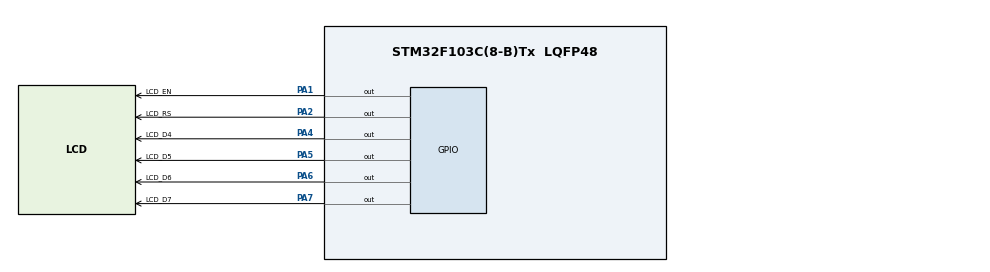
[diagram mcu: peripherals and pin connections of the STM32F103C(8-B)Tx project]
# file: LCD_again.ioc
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Mcu.Family=STM32F1
Mcu.Name=STM32F103C(8-B)Tx
Mcu.Package=LQFP48
NVIC.PriorityGroup=NVIC_PRIORITYGROUP_4
PA1.GPIO_Label=LCD_EN
PA1.Signal=GPIO_Output
PA13.Mode=Serial_Wire
PA13.Signal=SYS_JTMS-SWDIO
PA14.Mode=Serial_Wire
PA14.Signal=SYS_JTCK-SWCLK
PA2.GPIO_Label=LCD_RS
PA2.Signal=GPIO_Output
PA4.GPIO_Label=LCD_D4
PA4.Signal=GPIO_Output
PA5.GPIO_Label=LCD_D5
PA5.Signal=GPIO_Output
PA6.GPIO_Label=LCD_D6
PA6.Signal=GPIO_Output
PA7.GPIO_Label=LCD_D7
PA7.Signal=GPIO_Output
PD0-OSC_IN.Mode=HSE-External-Oscillator
PD0-OSC_IN.Signal=RCC_OSC_IN
PD1-OSC_OUT.Mode=HSE-External-Oscillator
PD1-OSC_OUT.Signal=RCC_OSC_OUT
ProjectManager.HeapSize=0x200
ProjectManager.StackSize=0x400
ProjectManager.TargetToolchain=MDK-ARM V5.32
RCC.APB1Freq_Value=8000000
RCC.APB2Freq_Value=8000000
board=custom

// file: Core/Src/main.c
/* USER CODE BEGIN Header */
/**
  ******************************************************************************
  * @file           : main.c
  * @brief          : Main program body
  ******************************************************************************
  * @attention
  *
  * Copyright (c) 2023 STMicroelectronics.
  * All rights reserved.
  *
  * This software is licensed under terms that can be found in the LICENSE file
  * in the root directory of this software component.
  * If no LICENSE file comes with this software, it is provided AS-IS.
  *
  ******************************************************************************
  */
/* USER CODE END Header */
#include "main.h"
#include "lcd16x2.h"

void SystemClock_Config(void);
static void MX_GPIO_Init(void);

int main(void)
{

  /* MCU Configuration--------------------------------------------------------*/

  /* Reset of all peripherals, Initializes the Flash interface and the Systick. */
  HAL_Init();

  /* Configure the system clock */
  SystemClock_Config();

  /* Initialize all configured peripherals */
  MX_GPIO_Init();
  /* USER CODE BEGIN 2 */
		lcd16x2_init_4bits(LCD_RS_GPIO_Port, LCD_RS_Pin, LCD_EN_Pin,
     // LCD_D4_GPIO_Port, LCD_D4_Pin, LCD_D5_Pin, LCD_D6_Pin, LCD_D7_Pin,
      LCD_D4_GPIO_Port, LCD_D4_Pin, LCD_D5_Pin, LCD_D6_Pin, LCD_D7_Pin);

			lcd16x2_1stLine();
			lcd16x2_printf("Hello again");
			HAL_Delay(1000);
			lcd16x2_clear();
  /* USER CODE END 2 */

  /* Infinite loop */
  while (1)
  {

    /* USER CODE BEGIN 3 */
		for(int i=0;i<16;i++)
		{
			lcd16x2_shiftRight(i);
			lcd16x2_1stLine();
			lcd16x2_printf("merhaba");
			HAL_Delay(200);
			lcd16x2_clear();

		}
	}
  /* USER CODE END 3 */
}

void SystemClock_Config(void)
{
  RCC_OscInitTypeDef RCC_OscInitStruct = {0};
  RCC_ClkInitTypeDef RCC_ClkInitStruct = {0};

  /** Initializes the RCC Oscillators according to the specified parameters
  * in the RCC_OscInitTypeDef structure.
  */
  RCC_OscInitStruct.OscillatorType = RCC_OSCILLATORTYPE_HSI;
  RCC_OscInitStruct.HSIState = RCC_HSI_ON;
  RCC_OscInitStruct.HSICalibrationValue = RCC_HSICALIBRATION_DEFAULT;
  RCC_OscInitStruct.PLL.PLLState = RCC_PLL_NONE;
  if (HAL_RCC_OscConfig(&RCC_OscInitStruct) != HAL_OK)
  {
    Error_Handler();
  }

  /** Initializes the CPU, AHB and APB buses clocks
  */
  RCC_ClkInitStruct.ClockType = RCC_CLOCKTYPE_HCLK|RCC_CLOCKTYPE_SYSCLK
                              |RCC_CLOCKTYPE_PCLK1|RCC_CLOCKTYPE_PCLK2;
  RCC_ClkInitStruct.SYSCLKSource = RCC_SYSCLKSOURCE_HSI;
  RCC_ClkInitStruct.AHBCLKDivider = RCC_SYSCLK_DIV1;
  RCC_ClkInitStruct.APB1CLKDivider = RCC_HCLK_DIV1;
  RCC_ClkInitStruct.APB2CLKDivider = RCC_HCLK_DIV1;

  if (HAL_RCC_ClockConfig(&RCC_ClkInitStruct, FLASH_LATENCY_0) != HAL_OK)
  {
    Error_Handler();
  }
}

static void MX_GPIO_Init(void)
{
  GPIO_InitTypeDef GPIO_InitStruct = {0};

  /* GPIO Ports Clock Enable */
  __HAL_RCC_GPIOD_CLK_ENABLE();
  __HAL_RCC_GPIOA_CLK_ENABLE();

  /*Configure GPIO pin Output Level */
  HAL_GPIO_WritePin(GPIOA, LCD_EN_Pin|LCD_RS_Pin|LCD_D4_Pin|LCD_D5_Pin
                          |LCD_D6_Pin|LCD_D7_Pin, GPIO_PIN_RESET);

  /*Configure GPIO pins : LCD_EN_Pin LCD_RS_Pin LCD_D4_Pin LCD_D5_Pin
                           LCD_D6_Pin LCD_D7_Pin */
  GPIO_InitStruct.Pin = LCD_EN_Pin|LCD_RS_Pin|LCD_D4_Pin|LCD_D5_Pin
                          |LCD_D6_Pin|LCD_D7_Pin;
  GPIO_InitStruct.Mode = GPIO_MODE_OUTPUT_PP;
  GPIO_InitStruct.Pull = GPIO_NOPULL;
  GPIO_InitStruct.Speed = GPIO_SPEED_FREQ_LOW;
  HAL_GPIO_Init(GPIOA, &GPIO_InitStruct);

}

void Error_Handler(void)
{
  __disable_irq();
  while (1)
  {
  }
}
